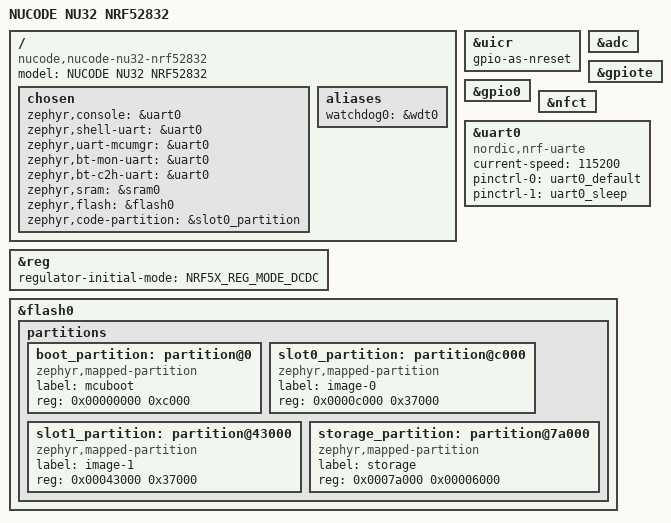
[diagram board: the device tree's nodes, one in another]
/*
 * Copyright (c) 2026 NUCODE Co., Ltd.
 *
 * SPDX-License-Identifier: Apache-2.0
 */

/dts-v1/;
#include <nordic/nrf52832_qfaa.dtsi>
#include "nucode_nu32_nrf52832-pinctrl.dtsi"

/ {
	model = "NUCODE NU32 NRF52832";
	compatible = "nucode,nucode-nu32-nrf52832";

	chosen {
		zephyr,console = &uart0;
		zephyr,shell-uart = &uart0;
		zephyr,uart-mcumgr = &uart0;
		zephyr,bt-mon-uart = &uart0;
		zephyr,bt-c2h-uart = &uart0;
		zephyr,sram = &sram0;
		zephyr,flash = &flash0;
		zephyr,code-partition = &slot0_partition;
	};

	aliases {
		watchdog0 = &wdt0;
	};
};

&reg {
	regulator-initial-mode = <NRF5X_REG_MODE_DCDC>;
};

&uicr {
	gpio-as-nreset;
};

&adc {
	status = "okay";
};

&gpiote {
	status = "okay";
};

&gpio0 {
	status = "okay";
};

&nfct {
	status = "okay";
};

&uart0 {
	compatible = "nordic,nrf-uarte";
	status = "okay";
	current-speed = <115200>;
	pinctrl-0 = <&uart0_default>;
	pinctrl-1 = <&uart0_sleep>;
	pinctrl-names = "default", "sleep";
};

&flash0 {
	partitions {
		ranges;
		#address-cells = <1>;
		#size-cells = <1>;

		boot_partition: partition@0 {
			compatible = "zephyr,mapped-partition";
			label = "mcuboot";
			reg = <0x00000000 0xc000>;
		};

		slot0_partition: partition@c000 {
			compatible = "zephyr,mapped-partition";
			label = "image-0";
			reg = <0x0000c000 0x37000>;
		};

		slot1_partition: partition@43000 {
			compatible = "zephyr,mapped-partition";
			label = "image-1";
			reg = <0x00043000 0x37000>;
		};

		storage_partition: partition@7a000 {
			compatible = "zephyr,mapped-partition";
			label = "storage";
			reg = <0x0007a000 0x00006000>;
		};
	};
};
